# GD32E53x register map
File version: 1.0
CPU: CM33 r0p4, little endian, MPU, FPU, 4 interrupt priority bits
Registers are 32-bit, read-write, reset 0x0 unless marked. A register's access mark holds for its fields unless they carry their own. Offsets are from the block's base; [hi:lo] are bit positions; 'fields as' and 'values as' point back to an identical list.

## OSPI — Octal-SPI interfac
Base 0x40025000
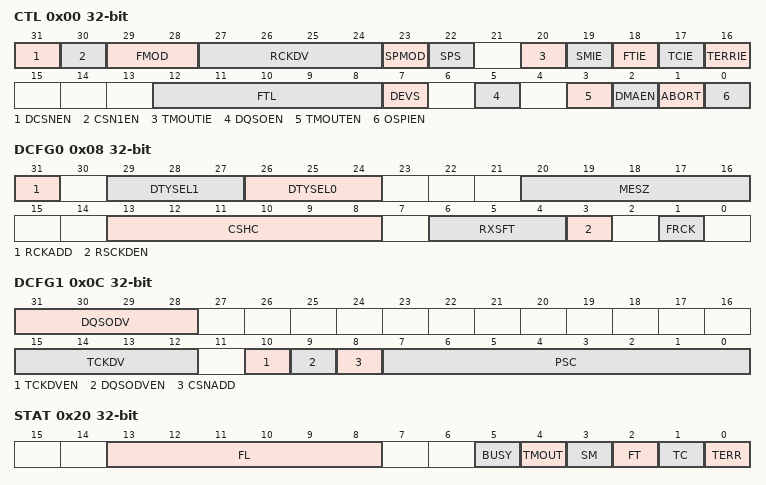
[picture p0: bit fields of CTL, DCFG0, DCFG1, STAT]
0x00 CTL — Control register
  [31] DCSNEN — Enable dual CSN mode
  [30] CSN1EN — Select to fix a specific CSN output (when not in memory-mapped mode)
  [29:28] FMOD — Functional mode
  [27:24] RCKDV — Receive SCK delay value
  [23] SPMOD — Status polling match mode
  [22] SPS — Status polling mode stop
  [20] TMOUTIE — Timeout interrupt enable
  [19] SMIE — Status match interrupt enable
  [18] FTIE — FIFO threshold interrupt enable
  [17] TCIE — Transfer complete interrupt enable
  [16] TERRIE — Transfer error interrupt enable
  [12:8] FTL — FIFO threshold level
  [7] DEVS — Device select
  [5] DQSOEN — DQS output enable
  [3] TMOUTEN — Timeout counter enable
  [2] DMAEN — DMA enable
  [1] ABORT — Abort request
  [0] OSPIEN — Enable OSPI
0x08 DCFG0 — Device configuration register 0
  [31] RCKADD — An additional clock is sent during reception, but the received data remains unchanged. To prevent DQS from missing an edge, configuration is required when choosing DQS for reception.
  [29:27] DTYSEL1 — When dual CSN mode is enabled, the Memory type corresponding to CSN1
  [26:24] DTYSEL0 — Select device type
  [20:16] MESZ — Memory size
  [13:8] CSHC — Chip select high cycle
  [6:4] RXSFT — Shift receive step if receive data delay more than 1/2 cycle.
  [3] RSCKDEN — Sampling delay enable
  [1] FRCK — This bit indicates the SCK is free running or not when OSPI is free.
0x0C DCFG1 — Device configuration register 1
  [31:28] DQSODV — DQS out transfer SCK delay chain value
  [15:12] TCKDV — SCK transfer delay chain value
  [10] TCKDVEN — SCK transfer delay enable
  [9] DQSODVEN — DQS out transfer SCK delay enable
  [8] CSNADD — CSN add 1/2 cycle
  [7:0] PSC — This field defines the scaler factor for generating SCK based on the kernel clock (value+1)
0x10 DCFG2 — Device configuration register 2
  [20:16] CSBND — Chip select boundary
0x14 DCFG3 — Device configuration register 3
  [31:0] REFRATE — Refresh rate
0x20 STAT ro — Status register
  [13:8] FL — FIFO level
  [5] BUSY
  [4] TMOUT — Timeout flag
  [3] SM — Status match flag
  [2] FT — FIFO threshold flag
  [1] TC — Transfer complete flag
  [0] TERR — Transfer error flag
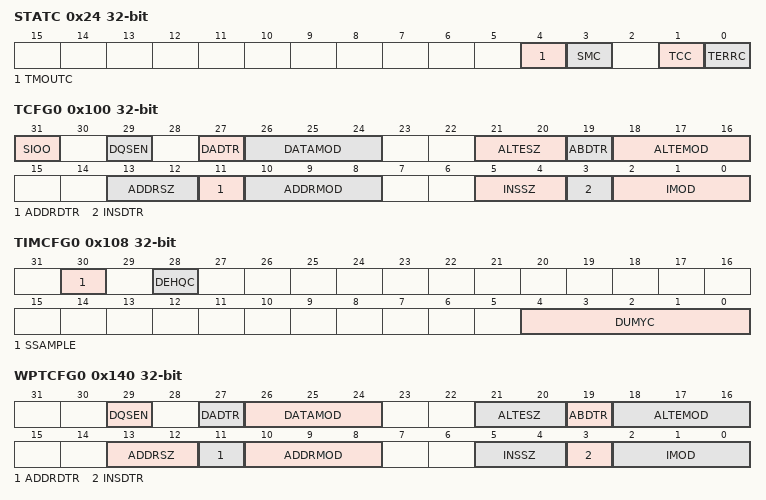
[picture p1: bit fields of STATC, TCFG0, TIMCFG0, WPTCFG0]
0x24 STATC wo — Status clear register
  [4] TMOUTC — Clear timeout flag
  [3] SMC — Clear status match flag
  [1] TCC — Clear transfer complete flag
  [0] TERRC — Clear transfer error flag
0x40 DTLEN — Data length register
  [31:0] DTLEN — Data length
0x48 ADDR — Address registe
  [31:0] ADDR — Address
0x50 DATA
0x80 STATMK — Status mask register
  [31:0] MASK — Status mask
0x88 STATMATCH — Status match registe
  [31:0] MATCH — Status match
0x90 INTERVAL
  [15:0] INTERVAL — Interval cycle
0x100 TCFG0 — Transfer configuration0 register
  [31] SIOO — Send instruction only once mode
  [29] DQSEN — DQS enable
  [27] DADTR — Data double transfer rate
  [26:24] DATAMOD — Data mode
  [21:20] ALTESZ — Alternate bytes size
  [19] ABDTR — Alternate bytes double transfer rate
  [18:16] ALTEMOD — Alternate bytes mode
  [13:12] ADDRSZ — Address size
  [11] ADDRDTR — Address double transfer rate
  [10:8] ADDRMOD — Address mode
  [5:4] INSSZ — Instruction size
  [3] INSDTR — Instruction double transfer rate
  [2:0] IMOD — Instruction mode
0x108 TIMCFG0 — Timing configuration0 register
  [30] SSAMPLE — Sample shift
  [28] DEHQC — Delay hold 1/4 cycle
  [4:0] DUMYC — Number of dummy cycles
0x110 INS0 — Instruction0 register
  [31:0] INSTRUCTION
0x120 ALTE0 — Alternate bytes0 register
  [31:0] ALTE — Alternate bytes
0x130 LPOUT — Low power timeout register
  [15:0] TIMEOUT — Timeout cycle
0x140 WPTCFG0 — Wrap transfer configuration0 register
  [29] DQSEN — DQS enable
  [27] DADTR — Data double transfer rate
  [26:24] DATAMOD — Data mode
  [21:20] ALTESZ — Alternate bytes size
  [19] ABDTR — Alternate bytes double transfer rate
  [18:16] ALTEMOD — Alternate bytes mode
  [13:12] ADDRSZ — Address size
  [11] ADDRDTR — Address double transfer rate
  [10:8] ADDRMOD — Address mode
  [5:4] INSSZ — Instruction size
  [3] INSDTR — Instruction double transfer rate
  [2:0] IMOD — Instruction mode
0x148 WPTIMCFG0 — Wrap timing configuration0 register
  [4:0] DUMYC — Number of dummy cycles
0x150 WPINS0 — Wrap instruction0 register
  [31:0] INSTRUCTION
0x160 WPALTE0 — Wrap alternate byte0 register
  [31:0] ALTE — Alternate bytes
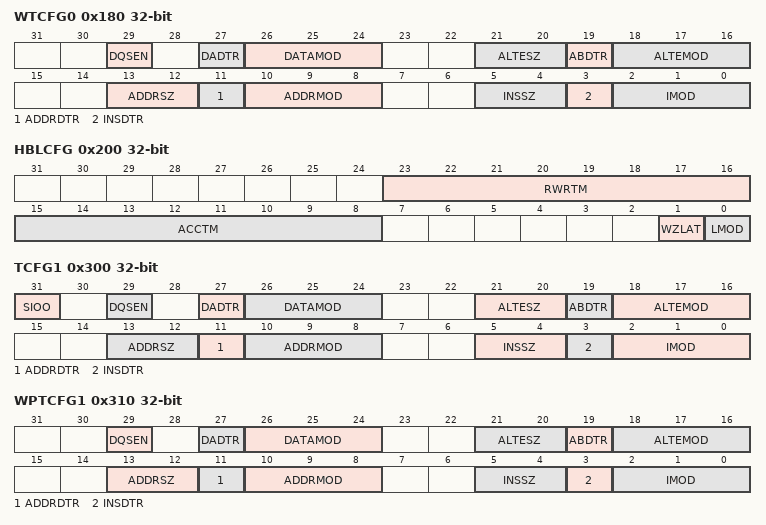
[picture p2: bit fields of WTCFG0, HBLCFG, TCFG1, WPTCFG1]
0x180 WTCFG0 — Write transfer configuration0 register
  fields as WPTCFG0
0x188 WTIMCFG0 — Write timing configuration0 register
  [4:0] DUMYC — Number of dummy cycles
0x190 WINS0 — Write instruction0 register
  [31:0] INSTRUCTION
0x1A0 WALTE0 — Write alternate byte0 register
  [31:0] ALTE — Alternate bytes
0x200 HBLCFG — HyperBusTM latency configuration register
  [23:16] RWRTM — Read write recovery time
  [15:8] ACCTM — Access time
  [1] WZLAT — Write zero latency
  [0] LMOD — Latency mode
0x300 TCFG1 — Transfer configuration1 register
  fields as TCFG0
0x304 TIMCFG1 — Timing configuration1 register
  [4:0] DUMYC — Number of dummy cycles
0x308 INS1 — Instruction1 register
  [31:0] INSTRUCTION
0x30C ALTE1 — Alternate1 bytes register
  [31:0] ALTE — Alternate bytes
0x310 WPTCFG1 — Wrap transfer configuration1 register
  fields as WPTCFG0
0x314 WPTIMCFG1 — Wrap timing configuration1 register
  [4:0] DUMYC — Number of dummy cycles
0x318 WPINS1 — Wrap instruction1 register
  [31:0] INSTRUCTION
0x31C WPALTE1 — Wrap alternate1 byte register
  [31:0] ALTE — Alternate bytes
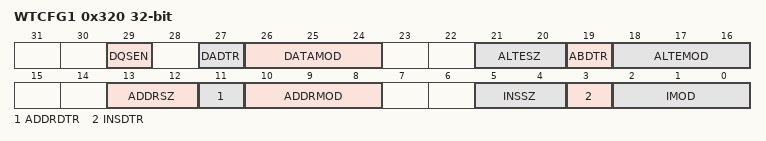
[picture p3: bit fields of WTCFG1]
0x320 WTCFG1 — Write transfer configuration1 register
  fields as WPTCFG0
0x324 WTIMCFG1 — Write timing configuration1 register
  [4:0] DUMYC — Number of dummy cycles
0x328 WINS1 — Write instruction1 register
  [31:0] INSTRUCTION
0x32C WALTE1 — Write alternate1 byte register
  [31:0] ALTE — Alternate bytes
